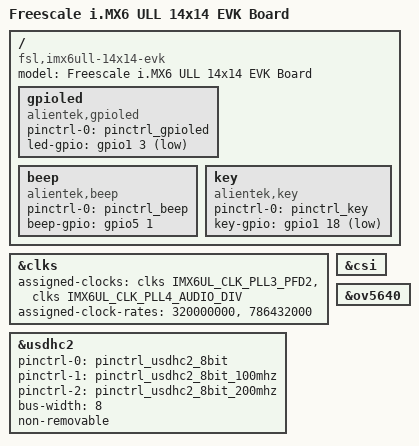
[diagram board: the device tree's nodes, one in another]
// SPDX-License-Identifier: (GPL-2.0 OR MIT)
//
// Copyright (C) 2016 Freescale Semiconductor, Inc.

/dts-v1/;

#include "imx6ull.dtsi"
#include "imx6ul-14x14-evk.dtsi"

/ {
	model = "Freescale i.MX6 ULL 14x14 EVK Board";
	compatible = "fsl,imx6ull-14x14-evk", "fsl,imx6ull";

	gpioled {
		compatible = "alientek,gpioled";
		pinctrl-names = "default";
		pinctrl-0 = <&pinctrl_gpioled>;
		status = "okay";
		led-gpio = <&gpio1 3 GPIO_ACTIVE_LOW>;
	};

	beep {
		compatible = "alientek,beep";
		pinctrl-names = "default";
		pinctrl-0 = <&pinctrl_beep>;
		beep-gpio = <&gpio5 1 GPIO_ACTIVE_HIGH>;
		status = "okay";
	};

	key {
		compatible = "alientek,key";
		pinctrl-names = "default";
		pinctrl-0 = <&pinctrl_key>;
		key-gpio = <&gpio1 18 GPIO_ACTIVE_LOW>;
		status = "okay";
	};
};

&clks {
	assigned-clocks = <&clks IMX6UL_CLK_PLL3_PFD2>,
			  <&clks IMX6UL_CLK_PLL4_AUDIO_DIV>;
	assigned-clock-rates = <320000000>, <786432000>;
};

&csi {
	status = "okay";
};

&ov5640 {
	status = "okay";
};

&usdhc2 {
	pinctrl-names = "default", "state_100mhz", "state_200mhz";
	pinctrl-0 = <&pinctrl_usdhc2_8bit>;
	pinctrl-1 = <&pinctrl_usdhc2_8bit_100mhz>;
	pinctrl-2 = <&pinctrl_usdhc2_8bit_200mhz>;
	bus-width = <8>;
	non-removable;
	status = "okay";
};

/delete-node/ &sim2;
